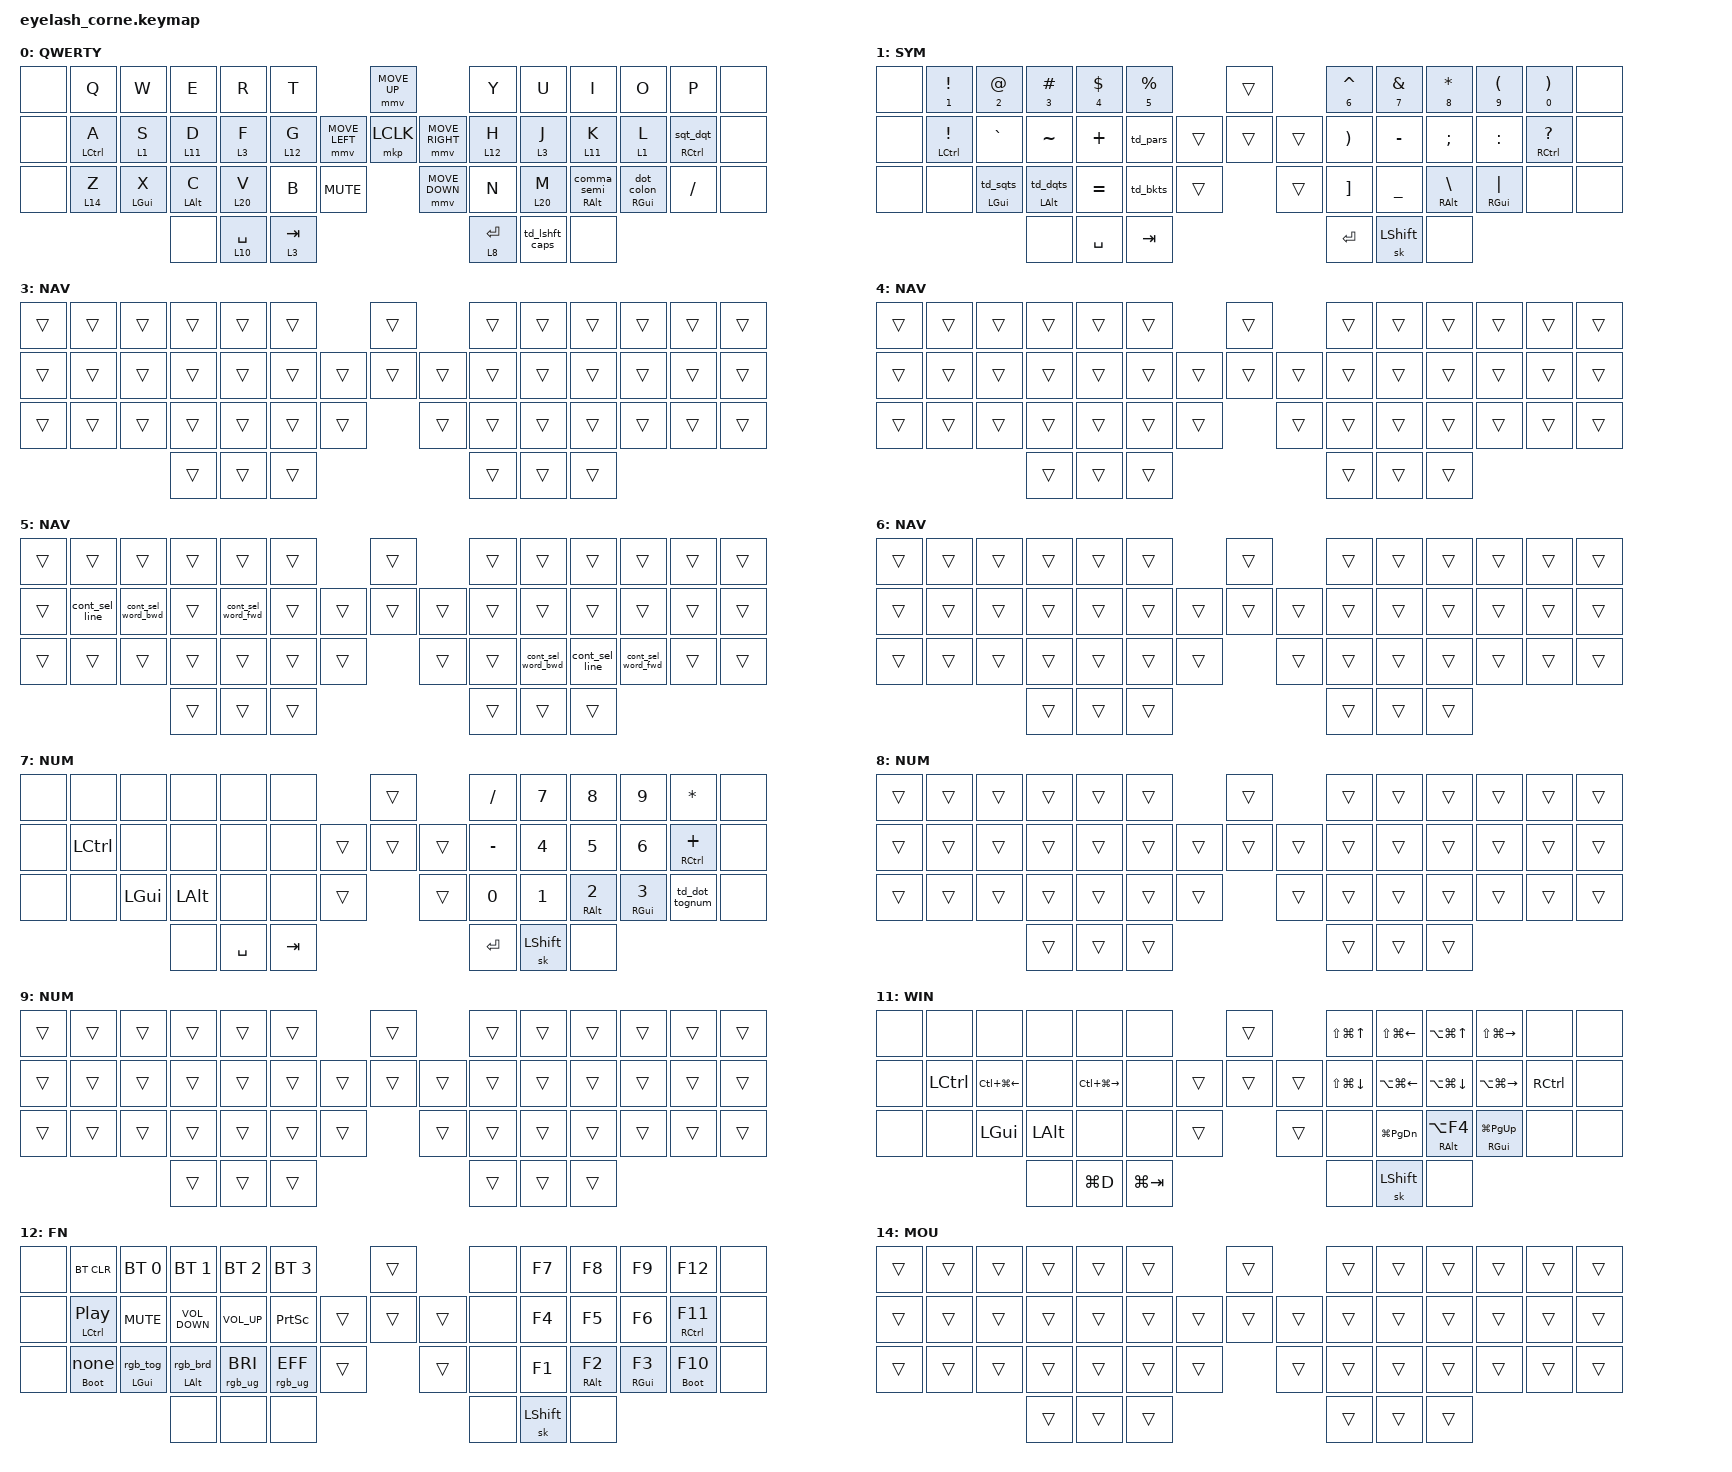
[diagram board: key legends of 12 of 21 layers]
#define ZMK_POINTING_DEFAULT_MOVE_VAL 400  // 600
#define ZMK_POINTING_DEFAULT_SCRL_VAL 100  // 10

#include <input/processors.dtsi>
#include <zephyr/dt-bindings/input/input-event-codes.h>
#include <behaviors.dtsi>
#include <dt-bindings/zmk/bt.h>
#include <dt-bindings/zmk/keys.h>
#include <dt-bindings/zmk/pointing.h>
#include <dt-bindings/zmk/rgb.h>

&mmv_input_listener { input-processors = <&zip_xy_scaler 2 1>; };

&msc_input_listener { input-processors = <&zip_scroll_scaler 2 1>; };

&msc {
    acceleration-exponent = <0>;      // 0
    time-to-max-speed-ms = <0>;       // 300
    delay-ms = <0>;                   // 0
};

&mmv {
    time-to-max-speed-ms = <200>;
    acceleration-exponent = <2>;
    trigger-period-ms = <16>;
};

&soft_off { hold-time-ms = <2000>; };

/ {
    behaviors {
        td_lshft_caps: td_lshft_caps {
            compatible = "zmk,behavior-tap-dance";
            display-name = "Shift/Caps Lock Tap Dance";
            #binding-cells = <0>;
            bindings = <&skq LEFT_SHIFT>, <&caps_word>, <&kp CAPS>;
        };

        td_bspc_bspcwd: td_bspc_bspcwd {
            compatible = "zmk,behavior-tap-dance";
            bindings = <&kp BSPC>, <&kp LC(BSPC)>;

            #binding-cells = <0>;
        };

        td_del_delwd: td_del_delwd {
            compatible = "zmk,behavior-tap-dance";
            bindings = <&kp DEL>, <&kp LC(DEL)>;

            #binding-cells = <0>;
        };

        td_pars: td_pars {
            compatible = "zmk,behavior-tap-dance";
            bindings = <&kp LPAR>, <&mc_pars>;

            #binding-cells = <0>;
        };

        td_abkts: td_abkts {
            compatible = "zmk,behavior-tap-dance";
            bindings = <&kp LESS_THAN>, <&mc_abkts>;

            #binding-cells = <0>;
        };

        td_bkts: td_bkts {
            compatible = "zmk,behavior-tap-dance";
            bindings = <&kp LBKT>, <&mc_bkts>;

            #binding-cells = <0>;
        };

        td_brcs: td_brcs {
            compatible = "zmk,behavior-tap-dance";
            bindings = <&kp LBRC>, <&mc_brcs>;

            #binding-cells = <0>;
        };

        td_sqts: td_sqts {
            compatible = "zmk,behavior-tap-dance";
            bindings = <&kp SQT>, <&mc_sqts>;

            #binding-cells = <0>;
        };

        td_dqts: td_dqts {
            compatible = "zmk,behavior-tap-dance";
            bindings = <&kp DQT>, <&mc_dqts>;

            #binding-cells = <0>;
        };

        td_tognav: td_tognav {
            compatible = "zmk,behavior-tap-dance";
            bindings = <&none>, <&tog 4>;

            #binding-cells = <0>;
        };

        td_dot_tognum: td_dot_tognum {
            compatible = "zmk,behavior-tap-dance";
            bindings = <&kp DOT>, <&tog 9>;

            #binding-cells = <0>;
        };

        td_togmou: td_togmou {
            compatible = "zmk,behavior-tap-dance";
            bindings = <&none>, <&tog 15>;

            #binding-cells = <0>;
        };

        mtq: mtq {
            compatible = "zmk,behavior-hold-tap";
            bindings = <&kp>, <&kp>;

            #binding-cells = <2>;
            tapping-term-ms = <200>;
            flavor = "balanced";
            quick-tap-ms = <175>;
        };

        mtq_mkp: mtq_mkp {
            compatible = "zmk,behavior-hold-tap";
            bindings = <&kp>, <&mkp>;

            #binding-cells = <2>;
            tapping-term-ms = <200>;
            flavor = "balanced";
            quick-tap-ms = <175>;
        };

        ltq: ltq {
            compatible = "zmk,behavior-hold-tap";
            bindings = <&mo>, <&kp>;

            #binding-cells = <2>;
            tapping-term-ms = <200>;
            flavor = "balanced";
            quick-tap-ms = <175>;
        };

        hml: hml {
            compatible = "zmk,behavior-hold-tap";
            bindings = <&kp>, <&kp>;

            #binding-cells = <2>;
            tapping-term-ms = <280>;
            require-prior-idle-ms = <150>;
            flavor = "balanced";
            quick-tap-ms = <175>;
            hold-trigger-on-release;
            hold-trigger-key-positions = <7 8 9 10 11 12 22 23 24 25 26 27 36 37 38 39 40 41 42 43 44 45 46 47>;
        };

        hmr: hmr {
            compatible = "zmk,behavior-hold-tap";
            bindings = <&kp>, <&kp>;

            #binding-cells = <2>;
            tapping-term-ms = <280>;
            require-prior-idle-ms = <150>;
            flavor = "balanced";
            quick-tap-ms = <175>;
            hold-trigger-on-release;
            hold-trigger-key-positions = <0 1 2 3 4 5 13 14 15 16 17 18 28 29 30 31 32 33 42 43 44 45 46 47 47>;
        };

        hml_sqt: hml_sqt {
            compatible = "zmk,behavior-hold-tap";
            bindings = <&kp>, <&td_sqts>;

            #binding-cells = <2>;
            tapping-term-ms = <280>;
            require-prior-idle-ms = <150>;
            flavor = "balanced";
            quick-tap-ms = <175>;
            hold-trigger-on-release;
            hold-trigger-key-positions = <7 8 9 10 11 12 22 23 24 25 26 27 36 37 38 39 40 41 42 43 44 45 46 47>;
        };

        hml_dqt: hml_dqt {
            compatible = "zmk,behavior-hold-tap";
            bindings = <&kp>, <&td_dqts>;

            #binding-cells = <2>;
            tapping-term-ms = <280>;
            require-prior-idle-ms = <150>;
            flavor = "balanced";
            quick-tap-ms = <175>;
            hold-trigger-on-release;
            hold-trigger-key-positions = <7 8 9 10 11 12 22 23 24 25 26 27 36 37 38 39 40 41 42 43 44 45 46 47>;
        };

        hml_sel_line: hml_sel_line {
            compatible = "zmk,behavior-hold-tap";
            bindings = <&kp>, <&sel_line>;

            #binding-cells = <2>;
            tapping-term-ms = <280>;
            require-prior-idle-ms = <150>;
            flavor = "balanced";
            quick-tap-ms = <175>;
            hold-trigger-on-release;
            hold-trigger-key-positions = <7 8 9 10 11 12 22 23 24 25 26 27 36 37 38 39 40 41 42 43 44 45 46 47>;
        };

        hml_rgb_tog: hml_rgb_tog {
            compatible = "zmk,behavior-hold-tap";
            bindings = <&kp>, <&rgb_tog>;

            #binding-cells = <2>;
            tapping-term-ms = <280>;
            require-prior-idle-ms = <150>;
            flavor = "balanced";
            quick-tap-ms = <175>;
            hold-trigger-on-release;
            hold-trigger-key-positions = <7 8 9 10 11 12 22 23 24 25 26 27 36 37 38 39 40 41 42 43 44 45 46 47>;
        };

        hml_rgb_brd: hml_rgb_brd {
            compatible = "zmk,behavior-hold-tap";
            bindings = <&kp>, <&rgb_brd>;

            #binding-cells = <2>;
            tapping-term-ms = <280>;
            require-prior-idle-ms = <150>;
            flavor = "balanced";
            quick-tap-ms = <175>;
            hold-trigger-on-release;
            hold-trigger-key-positions = <7 8 9 10 11 12 22 23 24 25 26 27 36 37 38 39 40 41 42 43 44 45 46 47>;
        };

        hmr_comma: hmr_comma {
            compatible = "zmk,behavior-hold-tap";
            bindings = <&kp>, <&comma_semi>;

            #binding-cells = <2>;
            tapping-term-ms = <280>;
            require-prior-idle-ms = <150>;
            flavor = "balanced";
            quick-tap-ms = <175>;
            hold-trigger-on-release;
            hold-trigger-key-positions = <0 1 2 3 4 5 13 14 15 16 17 18 28 29 30 31 32 33 42 43 44 45 46 47 47>;
        };

        hmr_dot: hmr_dot {
            compatible = "zmk,behavior-hold-tap";
            bindings = <&kp>, <&dot_colon>;

            #binding-cells = <2>;
            tapping-term-ms = <280>;
            require-prior-idle-ms = <150>;
            flavor = "balanced";
            quick-tap-ms = <175>;
            hold-trigger-on-release;
            hold-trigger-key-positions = <0 1 2 3 4 5 13 14 15 16 17 18 28 29 30 31 32 33 42 43 44 45 46 47 47>;
        };

        hmr_sqt: hmr_sqt {
            compatible = "zmk,behavior-hold-tap";
            bindings = <&kp>, <&sqt_dqt>;

            #binding-cells = <2>;
            tapping-term-ms = <280>;
            require-prior-idle-ms = <150>;
            flavor = "balanced";
            quick-tap-ms = <175>;
            hold-trigger-on-release;
            hold-trigger-key-positions = <0 1 2 3 4 5 13 14 15 16 17 18 28 29 30 31 32 33 42 43 44 45 46 47 47>;
        };

        hmr_sel_word_fwd: hmr_sel_word_fwd {
            compatible = "zmk,behavior-hold-tap";
            bindings = <&kp>, <&sel_word_fwd>;

            #binding-cells = <2>;
            tapping-term-ms = <280>;
            require-prior-idle-ms = <150>;
            flavor = "balanced";
            quick-tap-ms = <175>;
            hold-trigger-on-release;
            hold-trigger-key-positions = <0 1 2 3 4 5 13 14 15 16 17 18 28 29 30 31 32 33 42 43 44 45 46 47 47>;
        };

        hmr_sel_line: hmr_sel_line {
            compatible = "zmk,behavior-hold-tap";
            bindings = <&kp>, <&sel_line>;

            #binding-cells = <2>;
            tapping-term-ms = <280>;
            require-prior-idle-ms = <150>;
            flavor = "balanced";
            quick-tap-ms = <175>;
            hold-trigger-on-release;
            hold-trigger-key-positions = <0 1 2 3 4 5 13 14 15 16 17 18 28 29 30 31 32 33 42 43 44 45 46 47 47>;
        };

        hll: hll {
            compatible = "zmk,behavior-hold-tap";
            bindings = <&mo>, <&kp>;

            #binding-cells = <2>;
            tapping-term-ms = <280>;
            require-prior-idle-ms = <150>;
            flavor = "balanced";
            quick-tap-ms = <175>;
            hold-trigger-on-release;
            hold-trigger-key-positions = <7 8 9 10 11 12 22 23 24 25 26 27 36 37 38 39 40 41 42 43 44 45 46 47>;
        };

        hlr: hlr {
            compatible = "zmk,behavior-hold-tap";
            bindings = <&mo>, <&kp>;

            #binding-cells = <2>;
            tapping-term-ms = <280>;
            require-prior-idle-ms = <150>;
            flavor = "balanced";
            quick-tap-ms = <175>;
            hold-trigger-on-release;
            hold-trigger-key-positions = <0 1 2 3 4 5 13 14 15 16 17 18 28 29 30 31 32 33 42 43 44 45 46 47 47>;
        };

        as: as {
            compatible = "zmk,behavior-hold-tap";
            bindings = <&kp>, <&kp>;

            #binding-cells = <2>;
            tapping-term-ms = <135>;
            quick-tap-ms = <0>;
            flavor = "tap-preferred";
        };

        boot: boot {
            compatible = "zmk,behavior-hold-tap";
            bindings = <&bootloader>, <&none>;

            #binding-cells = <2>;
            tapping-term-ms = <2000>;
            flavor = "tap-preferred";
        };

        boot0: boot0 {
            compatible = "zmk,behavior-hold-tap";
            bindings = <&bootloader>, <&kp>;

            #binding-cells = <2>;
            tapping-term-ms = <2000>;
            flavor = "tap-preferred";
        };

        skq: skq {
            compatible = "zmk,behavior-sticky-key";
            bindings = <&kp>;
            #binding-cells = <1>;
            release-after-ms = <1000>;
            quick-release;
            ignore-modifiers;
        };

        sl_cont_sel: sl_cont_sel {
            compatible = "zmk,behavior-sticky-key";
            bindings = <&mo>;
            #binding-cells = <1>;
            release-after-ms = <5000>;
            quick-release;

            /delete-property/ ignore-modifiers;
        };

        lshft_caps: lshft_caps {
            compatible = "zmk,behavior-mod-morph";
            bindings = <&skq LEFT_SHIFT>, <&caps_word>;

            #binding-cells = <0>;
            mods = <(MOD_LSFT)>;
        };

        rshft_caps: rshft_caps {
            compatible = "zmk,behavior-mod-morph";
            bindings = <&skq RIGHT_SHIFT>, <&kp CAPS>;

            #binding-cells = <0>;
            mods = <(MOD_RSFT)>;
        };

        comma_semi: comma_semi {
            compatible = "zmk,behavior-mod-morph";
            bindings = <&kp COMMA>, <&kp SEMI>;

            #binding-cells = <0>;
            mods = <(MOD_LSFT|MOD_RSFT)>;
        };

        dot_colon: dot_colon {
            compatible = "zmk,behavior-mod-morph";
            bindings = <&kp DOT>, <&kp COLON>;

            #binding-cells = <0>;
            mods = <(MOD_LSFT|MOD_RSFT)>;
        };

        sqt_dqt: sqt_dqt {
            compatible = "zmk,behavior-mod-morph";
            bindings = <&td_sqts>, <&td_dqts>;

            #binding-cells = <0>;
            mods = <(MOD_LSFT|MOD_RSFT)>;
        };

        num_word: num_word {
            compatible = "zmk,behavior-auto-layer";
            #binding-cells = <1>;
            continue-list = <BSPC DEL DOT PLUS MINUS STAR FSLH>;
            ignore-numbers;
        };

        mou_word: mou_word {
            compatible = "zmk,behavior-auto-layer";
            #binding-cells = <1>;
            continue-list = <RET DOT COMMA FSLH SQT>;
            ignore-alphas;
            ignore-modifiers;
        };

        swapper: swapper {
            compatible = "zmk,behavior-tri-state";
            #binding-cells = <0>;
            bindings = <&kt LEFT_ALT>, <&kp TAB>, <&kt LEFT_ALT>;

            ignored-key-positions = <3>;
        };

        leader: leader {
            compatible = "zmk,behavior-leader-key";
            #binding-cells = <0>;
            ignore-keys = <LEFT_SHIFT RIGHT_SHIFT>;

            at {
                sequence = <A T>;
                bindings = <&kp AT>;
            };

            hash {
                sequence = <H A>;
                bindings = <&kp HASH>;
            };

            dllr {
                sequence = <D O>;
                bindings = <&kp DLLR>;
            };

            prcnt {
                sequence = <P C>;
                bindings = <&kp PRCNT>;
            };

            caret {
                sequence = <C T>;
                bindings = <&kp CARET>;
            };

            amps {
                sequence = <A M>;
                bindings = <&kp AMPS>;
            };
        };
    };

    rgb_encoder: rgb_encoder {
        compatible = "zmk,behavior-sensor-rotate";
        #sensor-binding-cells = <0>;
        bindings = <&rgb_ug RGB_BRI>, <&rgb_ug RGB_BRD>;
    };

    scroll_encoder: scroll_encoder {
        compatible = "zmk,behavior-sensor-rotate";
        #sensor-binding-cells = <0>;
        bindings = <&msc SCRL_DOWN>, <&msc SCRL_UP>;

        tap-ms = <100>;
    };

    combos {
        compatible = "zmk,combos";

        combo_softoff {
            bindings = <&soft_off>;
            key-positions = <1 15 29>;
            layers = <0>;
        };

        combo_esc {
            bindings = <&kp ESC>;
            key-positions = <15 16>;
            layers = <0 8 19>;
            timeout-ms = <30>;
            require-prior-idle-ms = <150>;
        };

        combo_esc0 {
            bindings = <&kp ESC>;
            key-positions = <36 37>;
            layers = <8>;
        };

        combo_esc1 {
            bindings = <&kp ESC>;
            key-positions = <22 23>;
            layers = <19>;
        };

        combo_tobse {
            bindings = <&to 0>;
            key-positions = <2 3>;
            layers = <15>;
        };

        combo_tobse0 {
            bindings = <&to 0>;
            key-positions = <15 16>;
            layers = <15>;
        };

        combo_leftshift {
            bindings = <&kp LEFT_SHIFT>;
            key-positions = <17 18>;
            timeout-ms = <50>;
            require-prior-idle-ms = <150>;
            layers = <0>;
        };

        combo_numword {
            bindings = <&num_word 8>;
            key-positions = <36 37>;
            timeout-ms = <50>;
            require-prior-idle-ms = <150>;
            layers = <0>;
        };

        combo_mouword {
            bindings = <&mou_macro>;
            key-positions = <22 23>;
            timeout-ms = <50>;
            require-prior-idle-ms = <150>;
            layers = <0>;
        };

        combo_leader {
            bindings = <&leader>;
            key-positions = <3 4>;
            timeout-ms = <20>;
            require-prior-idle-ms = <150>;
            layers = <0>;
        };

        combo_tomou {
            bindings = <&to 15>;
            key-positions = <2 3>;
            timeout-ms = <20>;
            require-prior-idle-ms = <150>;
            layers = <0>;
        };

        combo_tab {
            bindings = <&kp TAB>;
            key-positions = <16 17>;
            layers = <0 1 3 4 6 8 9>;
            timeout-ms = <50>;
            require-prior-idle-ms = <150>;
        };

        combo_ret {
            bindings = <&kp RET>;
            key-positions = <37 38>;
            timeout-ms = <50>;
            require-prior-idle-ms = <150>;
            layers = <0 1 3 4 6 8 9>;
        };

        combo_bspc {
            bindings = <&kp BSPC>;
            key-positions = <23 24>;
            layers = <0 1 3 4 6 8 9>;
            timeout-ms = <50>;
            require-prior-idle-ms = <150>;
        };

        combo_bspcwd {
            bindings = <&kp LC(BSPC)>;
            key-positions = <8 9>;
            timeout-ms = <30>;
            require-prior-idle-ms = <150>;
            layers = <0 1 3 4 6 8 9>;
        };

        combo_del {
            bindings = <&kp DEL>;
            key-positions = <24 25>;
            layers = <0 1 3 4 6 8 9>;
            timeout-ms = <30>;
            require-prior-idle-ms = <150>;
        };

        combo_delwd {
            bindings = <&kp LC(DEL)>;
            key-positions = <9 10>;
            timeout-ms = <20>;
            require-prior-idle-ms = <150>;
            layers = <0 1 3 4 6 8 9>;
        };

        combo_selall {
            bindings = <&kp LC(A)>;
            key-positions = <14 17>;
            timeout-ms = <30>;
            require-prior-idle-ms = <150>;
            layers = <0 1 3 4 6 8 9>;
        };

        combo_save {
            bindings = <&kp LC(S)>;
            key-positions = <15 17>;
            timeout-ms = <30>;
            require-prior-idle-ms = <150>;
            layers = <0 1 3 4 6 8 9>;
        };

        combo_undo {
            bindings = <&kp LC(Z)>;
            key-positions = <29 30>;
            timeout-ms = <50>;
            require-prior-idle-ms = <150>;
            layers = <0 1 3 4 6 8 9>;
        };

        combo_redo {
            bindings = <&kp LC(LS(Z))>;
            key-positions = <29 31>;
            timeout-ms = <50>;
            require-prior-idle-ms = <150>;
            layers = <0 1 3 4 6 8 9>;
        };

        combo_cut {
            bindings = <&kp LC(X)>;
            key-positions = <30 32>;
            timeout-ms = <50>;
            require-prior-idle-ms = <150>;
            layers = <0 1 3 4 6 8 9>;
        };

        combo_copy {
            bindings = <&kp LC(INS)>;
            key-positions = <30 31>;
            timeout-ms = <30>;
            require-prior-idle-ms = <150>;
            layers = <0 1 3 4 6 8 9>;
        };

        combo_paste {
            bindings = <&kp LS(INS)>;
            key-positions = <31 32>;
            timeout-ms = <50>;
            require-prior-idle-ms = <150>;
            layers = <0 1 3 4 6 8 9>;
        };

        combo_grave {
            bindings = <&kp GRAVE>;
            key-positions = <2 15>;
            timeout-ms = <50>;
            require-prior-idle-ms = <150>;
            layers = <0>;
        };

        combo_tilde {
            bindings = <&kp TILDE>;
            key-positions = <3 16>;
            timeout-ms = <50>;
            require-prior-idle-ms = <150>;
            layers = <0>;
        };

        combo_plus {
            bindings = <&kp PLUS>;
            key-positions = <4 17>;
            timeout-ms = <50>;
            require-prior-idle-ms = <150>;
            layers = <0>;
        };

        combo_lpar {
            bindings = <&td_pars>;
            key-positions = <5 18>;
            timeout-ms = <50>;
            require-prior-idle-ms = <150>;
            layers = <0>;
        };

        combo_rpar {
            bindings = <&kp RPAR>;
            key-positions = <7 22>;
            timeout-ms = <50>;
            require-prior-idle-ms = <150>;
            layers = <0>;
        };

        combo_minus {
            bindings = <&kp MINUS>;
            key-positions = <8 23>;
            timeout-ms = <50>;
            require-prior-idle-ms = <150>;
            layers = <0>;
        };

        combo_semi {
            bindings = <&kp SEMI>;
            key-positions = <9 24>;
            timeout-ms = <50>;
            require-prior-idle-ms = <150>;
            layers = <0>;
        };

        combo_colon {
            bindings = <&kp COLON>;
            key-positions = <10 25>;
            timeout-ms = <50>;
            require-prior-idle-ms = <150>;
            layers = <0>;
        };

        combo_excl {
            bindings = <&kp EXCL>;
            key-positions = <15 30>;
            timeout-ms = <50>;
            require-prior-idle-ms = <150>;
            layers = <0>;
        };

        combo_equal {
            bindings = <&kp EQUAL>;
            key-positions = <17 32>;
            timeout-ms = <50>;
            require-prior-idle-ms = <150>;
            layers = <0>;
        };

        combo_lbkt {
            bindings = <&td_bkts>;
            key-positions = <18 33>;
            timeout-ms = <50>;
            require-prior-idle-ms = <150>;
            layers = <0>;
        };

        combo_rbkt {
            bindings = <&kp RBKT>;
            key-positions = <22 36>;
            timeout-ms = <50>;
            require-prior-idle-ms = <150>;
            layers = <0>;
        };

        combo_under {
            bindings = <&kp UNDER>;
            key-positions = <23 37>;
            timeout-ms = <50>;
            require-prior-idle-ms = <150>;
            layers = <0>;
        };

        combo_question {
            bindings = <&kp QUESTION>;
            key-positions = <25 39>;
            timeout-ms = <50>;
            require-prior-idle-ms = <150>;
            layers = <0>;
        };

        combo_lbrc {
            bindings = <&td_brcs>;
            key-positions = <32 33>;
            layers = <1>;
        };

        combo_rbrc {
            bindings = <&kp RBRC>;
            key-positions = <36 37>;
            layers = <1>;
        };

        combo_lessthan {
            bindings = <&td_abkts>;
            key-positions = <17 18>;
            layers = <1>;
        };

        combo_greaterthan {
            bindings = <&kp GREATER_THAN>;
            key-positions = <22 23>;
            layers = <1>;
        };

        combo_mb4 {
            bindings = <&mkp MB4>;
            key-positions = <8 9>;
            layers = <14 15 16 17 18 19>;
        };

        combo_mb5 {
            bindings = <&mkp MB5>;
            key-positions = <9 10>;
            layers = <14 15 16 17 18 19>;
        };
    };

    macros {
        sel_word_fwd: sel_word_fwd {
            compatible = "zmk,behavior-macro";
            #binding-cells = <0>;
            bindings =
                <&macro_tap>,
                <&kp LC(RIGHT) &kp LC(LEFT)>,
                <&macro_press>,
                <&kp LC(LS(RIGHT))>,
                <&macro_pause_for_release>,
                <&macro_release>,
                <&kp LC(LS(RIGHT))>,
                <&macro_tap>,
                <&sl_cont_sel 6>;

            wait-ms = <0>;
            tap-ms = <0>;
        };

        sel_word_bwd: sel_word_bwd {
            compatible = "zmk,behavior-macro";
            #binding-cells = <0>;
            bindings =
                <&macro_tap>,
                <&kp LC(LEFT) &kp LC(RIGHT)>,
                <&macro_press>,
                <&kp LC(LS(LEFT))>,
                <&macro_pause_for_release>,
                <&macro_release>,
                <&kp LC(LS(LEFT))>,
                <&macro_tap>,
                <&sl_cont_sel 6>;

            wait-ms = <0>;
            tap-ms = <0>;
        };

        sel_line: sel_line {
            compatible = "zmk,behavior-macro";
            #binding-cells = <0>;
            bindings =
                <&macro_tap>,
                <&kp HOME &kp LS(END)>,
                <&macro_tap>,
                <&sl_cont_sel 6>;

            wait-ms = <0>;
            tap-ms = <0>;
        };

        cont_sel_word_fwd: cont_sel_word_fwd {
            compatible = "zmk,behavior-macro";
            #binding-cells = <0>;
            bindings =
                <&macro_press>,
                <&kp LC(LS(RIGHT))>,
                <&macro_pause_for_release>,
                <&macro_release>,
                <&kp LC(LS(RIGHT))>,
                <&macro_tap>,
                <&sl_cont_sel 6>;

            wait-ms = <0>;
            tap-ms = <0>;
        };

        cont_sel_word_bwd: cont_sel_word_bwd {
            compatible = "zmk,behavior-macro";
            #binding-cells = <0>;
            bindings =
                <&macro_press>,
                <&kp LC(LS(LEFT))>,
                <&macro_pause_for_release>,
                <&macro_release>,
                <&kp LC(LS(LEFT))>,
                <&macro_tap>,
                <&sl_cont_sel 6>;

            wait-ms = <0>;
            tap-ms = <0>;
        };

        cont_sel_line: cont_sel_line {
            compatible = "zmk,behavior-macro";
            #binding-cells = <0>;
            bindings =
                <&macro_press>,
                <&kp LS(DOWN)>,
                <&macro_pause_for_release>,
                <&macro_release>,
                <&kp LS(DOWN)>,
                <&macro_tap>,
                <&kp LS(END)>,
                <&macro_tap>,
                <&sl_cont_sel 6>;

            wait-ms = <0>;
            tap-ms = <0>;
        };

        mou_macro: mou_macro {
            compatible = "zmk,behavior-macro";
            #binding-cells = <0>;
            bindings = <&kp LEFT_CONTROL &mou_word 19>;
            wait-ms = <0>;
            tap-ms = <0>;
        };

        mc_pars: mc_pars {
            compatible = "zmk,behavior-macro";
            #binding-cells = <0>;
            bindings = <&kp LPAR &kp RPAR &kp LEFT>;
            wait-ms = <0>;
            tap-ms = <0>;
        };

        mc_abkts: mc_abkts {
            compatible = "zmk,behavior-macro";
            #binding-cells = <0>;
            bindings = <&kp LESS_THAN &kp GREATER_THAN &kp LEFT>;
            wait-ms = <0>;
            tap-ms = <0>;
        };

        mc_bkts: mc_bkts {
            compatible = "zmk,behavior-macro";
            #binding-cells = <0>;
            bindings = <&kp LBKT &kp RBKT &kp LEFT>;
            wait-ms = <0>;
            tap-ms = <0>;
        };

        mc_brcs: mc_brcs {
            compatible = "zmk,behavior-macro";
            #binding-cells = <0>;
            bindings = <&kp LBRC &kp RBRC &kp LEFT>;
            wait-ms = <0>;
            tap-ms = <0>;
        };

        mc_sqts: mc_sqts {
            compatible = "zmk,behavior-macro";
            #binding-cells = <0>;
            bindings = <&kp SQT &kp SQT &kp LEFT>;
            wait-ms = <0>;
            tap-ms = <0>;
        };

        mc_dqts: mc_dqts {
            compatible = "zmk,behavior-macro";
            #binding-cells = <0>;
            bindings = <&kp DQT &kp DQT &kp LEFT>;
            wait-ms = <0>;
            tap-ms = <0>;
        };

        rgb_tog: rgb_tog {
            compatible = "zmk,behavior-macro";
            #binding-cells = <0>;
            bindings = <&rgb_ug RGB_TOG>;
            wait-ms = <0>;
            tap-ms = <0>;
        };

        rgb_brd: rgb_brd {
            compatible = "zmk,behavior-macro";
            #binding-cells = <0>;
            bindings = <&rgb_ug RGB_BRD>;
            wait-ms = <0>;
            tap-ms = <0>;
        };
    };

    keymap {
        compatible = "zmk,keymap";

        base {
            display-name = "QWERTY";
            bindings = <
&none  &kp Q                &kp W        &kp E            &kp R          &kp T                                     &mmv MOVE_UP                     &kp Y       &kp U           &kp I                   &kp O            &kp P                     &none
&none  &hml LEFT_CONTROL A  &hll 1 S     &hll 11 D        &hll 3 F       &hll 12 G                 &mmv MOVE_LEFT  &mkp LCLK       &mmv MOVE_RIGHT  &hlr 12 H   &hlr 3 J        &hlr 11 K               &hlr 1 L         &hmr_sqt RIGHT_CONTROL 0  &none
&none  &hll 14 Z            &hml LGUI X  &hml LEFT_ALT C  &hll 20 V      &kp B       &kp C_MUTE                    &mmv MOVE_DOWN                   &kp N       &hlr 20 M       &hmr_comma RIGHT_ALT 0  &hmr_dot RGUI 0  &kp SLASH                 &none
                                         &none            &ltq 10 SPACE  &ltq 3 TAB                                                                 &ltq 8 RET  &td_lshft_caps  &none
            >;

            sensor-bindings = <&inc_dec_kp C_VOLUME_UP C_VOLUME_DOWN>;
        };

        symbol {
            display-name = "SYM";
            bindings = <
&none  &as N1 EXCL             &as N2 AT        &as N3 HASH          &as N4 DLLR  &as N5 PRCNT                    &trans          &as N6 CARET  &as N7 AMPS     &as N8 ASTRK         &as N9 LPAR     &as N0 RPAR                  &none
&none  &hml LEFT_CONTROL EXCL  &kp GRAVE        &kp TILDE            &kp PLUS     &td_pars                &trans  &trans  &trans  &kp RPAR      &kp MINUS       &kp SEMI             &kp COLON       &hmr RIGHT_CONTROL QUESTION  &none
&none  &none                   &hml_sqt LGUI 0  &hml_dqt LEFT_ALT 0  &kp EQUAL    &td_bkts      &trans            &trans          &kp RBKT      &kp UNDER       &hmr RIGHT_ALT BSLH  &hmr RGUI PIPE  &none                        &none
                                                &none                &kp SPACE    &kp TAB                                         &kp RET       &sk LEFT_SHIFT  &none
            >;

            sensor-bindings = <&scroll_encoder>;
        };

        navigation {
            display-name = "NAV";
            bindings = <
&none  &none                         &none            &none                  &none          &none                      &trans          &kp PG_UP  &as HOME LC(LEFT)  &kp UP                     &as END LC(RIGHT)         &kp LA(LC(LS(LG(P))))  &none
&none  &hml_sel_line LEFT_CONTROL 0  &sel_word_bwd    &none                  &sel_word_fwd  &none              &trans  &trans  &trans  &kp PG_DN  &kp LEFT           &kp DOWN                   &kp RIGHT                 &kp RIGHT_CONTROL      &none
&none  &kp LC(Z)                     &hml LGUI LC(X)  &hml LEFT_ALT LC(INS)  &kp LS(INS)    &none    &trans            &trans          &none      &sel_word_bwd      &hmr_sel_line RIGHT_ALT 0  &hmr_sel_word_fwd RGUI 0  &td_tognav             &none
                                                      &none                  &kp SPACE      &kp TAB                                    &kp RET    &sk LEFT_SHIFT     &none
            >;

            sensor-bindings = <&scroll_encoder>;
        };

        navigation_momentary {
            display-name = "NAV ";
            bindings = <
&trans  &trans  &trans  &trans  &trans  &trans                    &trans          &trans  &trans  &trans  &trans  &trans  &trans
&trans  &trans  &trans  &trans  &trans  &trans            &trans  &trans  &trans  &trans  &trans  &trans  &trans  &trans  &trans
&trans  &trans  &trans  &trans  &trans  &trans  &trans            &trans          &trans  &trans  &trans  &trans  &trans  &trans
                        &trans  &trans  &trans                                    &trans  &trans  &trans
            >;

            sensor-bindings = <&scroll_encoder>;
        };

        navigation_lock {
            display-name = "NAV ";
            bindings = <
&trans  &trans  &trans  &trans  &trans  &trans                    &trans          &trans  &trans  &trans  &trans  &trans  &trans
&trans  &trans  &trans  &trans  &trans  &trans            &trans  &trans  &trans  &trans  &trans  &trans  &trans  &trans  &trans
&trans  &trans  &trans  &trans  &trans  &trans  &trans            &trans          &trans  &trans  &trans  &trans  &trans  &trans
                        &trans  &trans  &trans                                    &trans  &trans  &trans
            >;

            sensor-bindings = <&scroll_encoder>;
        };

        navigation_cont_sel {
            display-name = "NAV ";
            bindings = <
&trans  &trans          &trans              &trans  &trans              &trans                    &trans          &trans  &trans              &trans          &trans              &trans  &trans
&trans  &cont_sel_line  &cont_sel_word_bwd  &trans  &cont_sel_word_fwd  &trans            &trans  &trans  &trans  &trans  &trans              &trans          &trans              &trans  &trans
&trans  &trans          &trans              &trans  &trans              &trans  &trans            &trans          &trans  &cont_sel_word_bwd  &cont_sel_line  &cont_sel_word_fwd  &trans  &trans
                                            &trans  &trans              &trans                                    &trans  &trans              &trans
            >;

            sensor-bindings = <&scroll_encoder>;
        };

        navigation_cont_sel_sl {
            display-name = "NAV ";
            bindings = <
&trans  &trans  &trans  &trans  &trans  &trans                    &trans          &trans  &trans  &trans  &trans  &trans  &trans
&trans  &trans  &trans  &trans  &trans  &trans            &trans  &trans  &trans  &trans  &trans  &trans  &trans  &trans  &trans
&trans  &trans  &trans  &trans  &trans  &trans  &trans            &trans          &trans  &trans  &trans  &trans  &trans  &trans
                        &trans  &trans  &trans                                    &trans  &trans  &trans
            >;

            sensor-bindings = <&scroll_encoder>;
        };

        numpad {
            display-name = "NUM";
            bindings = <
&none  &none             &none     &none         &none      &none                      &trans          &kp FSLH   &kp N7          &kp N8             &kp N9        &kp STAR                 &none
&none  &kp LEFT_CONTROL  &none     &none         &none      &none              &trans  &trans  &trans  &kp MINUS  &kp N4          &kp N5             &kp N6        &hmr RIGHT_CONTROL PLUS  &none
&none  &none             &kp LGUI  &kp LEFT_ALT  &none      &none    &trans            &trans          &kp N0     &kp NUMBER_1    &hmr RIGHT_ALT N2  &hmr RGUI N3  &td_dot_tognum           &none
                                   &none         &kp SPACE  &kp TAB                                    &kp RET    &sk LEFT_SHIFT  &none
            >;

            sensor-bindings = <&scroll_encoder>;
        };

        numpad_momentary {
            display-name = "NUM ";
            bindings = <
&trans  &trans  &trans  &trans  &trans  &trans                    &trans          &trans  &trans  &trans  &trans  &trans  &trans
&trans  &trans  &trans  &trans  &trans  &trans            &trans  &trans  &trans  &trans  &trans  &trans  &trans  &trans  &trans
&trans  &trans  &trans  &trans  &trans  &trans  &trans            &trans          &trans  &trans  &trans  &trans  &trans  &trans
                        &trans  &trans  &trans                                    &trans  &trans  &trans
            >;

            sensor-bindings = <&scroll_encoder>;
        };

        numpad_lock {
            display-name = "NUM ";
            bindings = <
&trans  &trans  &trans  &trans  &trans  &trans                    &trans          &trans  &trans  &trans  &trans  &trans  &trans
&trans  &trans  &trans  &trans  &trans  &trans            &trans  &trans  &trans  &trans  &trans  &trans  &trans  &trans  &trans
&trans  &trans  &trans  &trans  &trans  &trans  &trans            &trans          &trans  &trans  &trans  &trans  &trans  &trans
                        &trans  &trans  &trans                                    &trans  &trans  &trans
            >;

            sensor-bindings = <&scroll_encoder>;
        };

        application {
            display-name = "APP";
            bindings = <
&none  &none  &none              &kp LS(TAB)        &swapper           &kp LA(LC(LS(T)))                    &trans          &kp LA(LC(LS(Y)))  &none  &kp LA(LC(LS(I)))  &none  &none  &none
&none  &none  &kp LA(LC(LS(S)))  &none              &kp LA(LC(LS(F)))  &kp LA(LC(LS(G)))            &trans  &trans  &trans  &none              &none  &kp LA(LC(LS(K)))  &none  &none  &none
&none  &none  &none              &kp LA(LC(LS(C)))  &none              &none              &trans            &trans          &kp LA(LC(LS(N)))  &none  &none              &none  &none  &none
                                 &none              &none              &none                                                &none              &none  &none
            >;

            sensor-bindings = <&scroll_encoder>;
        };

        window {
            display-name = "WIN";
            bindings = <
&none  &none             &none                   &none         &none              &none                          &trans          &kp LS(LG(UP))    &kp LS(LG(LEFT))        &kp LA(LG(UP))          &kp LS(LG(RIGHT))    &none              &none
&none  &kp LEFT_CONTROL  &kp LC(LG(LEFT_ARROW))  &none         &kp LC(LG(RIGHT))  &none                  &trans  &trans  &trans  &kp LS(LG(DOWN))  &kp LA(LG(LEFT_ARROW))  &kp LA(LG(DOWN_ARROW))  &kp LA(LG(RIGHT))    &kp RIGHT_CONTROL  &none
&none  &none             &kp LGUI                &kp LEFT_ALT  &none              &none        &trans            &trans          &none             &kp LG(PG_DN)           &hmr RIGHT_ALT LA(F4)   &hmr RGUI LG(PG_UP)  &none              &none
                                                 &none         &kp LG(D)          &kp LG(TAB)                                    &none             &sk LEFT_SHIFT          &none
            >;

            sensor-bindings = <&scroll_encoder>;
        };

        function {
            display-name = "FN";
            bindings = <
&none  &bt BT_CLR                      &bt BT_SEL 0         &bt BT_SEL 1             &bt BT_SEL 2     &bt BT_SEL 3                       &trans          &none  &kp F7          &kp F8             &kp F9        &kp F12                 &none
&none  &hml LEFT_CONTROL C_PLAY_PAUSE  &kp C_MUTE           &kp C_VOLUME_DOWN        &kp C_VOLUME_UP  &kp PRINTSCREEN            &trans  &trans  &trans  &none  &kp F4          &kp F5             &kp F6        &hmr RIGHT_CONTROL F11  &none
&none  &boot 0 0                       &hml_rgb_tog LGUI 0  &hml_rgb_brd LEFT_ALT 0  &rgb_ug RGB_BRI  &rgb_ug RGB_EFF  &trans            &trans          &none  &kp F1          &hmr RIGHT_ALT F2  &hmr RGUI F3  &boot0 0 F10            &none
                                                            &none                    &none            &none                                              &none  &sk LEFT_SHIFT  &none
            >;

            sensor-bindings = <&scroll_encoder>;
        };

        mouse {
            display-name = "MOU";
            bindings = <
&none  &none             &none   &none   &none      &none                    &trans          &msc SCRL_UP    &mkp LCLK                 &mmv MOVE_UP    &mkp RCLK        &kp LA(LC(LS(LG(P))))  &none
&none  &kp LEFT_CONTROL  &mo 16  &mo 17  &mo 18     &none            &trans  &trans  &trans  &msc SCRL_DOWN  &mmv MOVE_LEFT            &mmv MOVE_DOWN  &mmv MOVE_RIGHT  &kp RIGHT_CONTROL      &none
&none  &none             &none   &none   &none      &none  &trans            &trans          &none           &msc SCRL_LEFT            &mkp MCLK       &msc SCRL_RIGHT  &td_togmou             &none
                                 &none   &mkp LCLK  &none                                    &none           &mtq_mkp LEFT_SHIFT LCLK  &none
            >;

            sensor-bindings = <&scroll_encoder>;
        };

        mouse_momentary {
            display-name = "MOU ";
            bindings = <
&trans  &trans  &trans  &trans  &trans  &trans                    &trans          &trans  &trans  &trans  &trans  &trans  &trans
&trans  &trans  &trans  &trans  &trans  &trans            &trans  &trans  &trans  &trans  &trans  &trans  &trans  &trans  &trans
&trans  &trans  &trans  &trans  &trans  &trans  &trans            &trans          &trans  &trans  &trans  &trans  &trans  &trans
                        &trans  &trans  &trans                                    &trans  &trans  &trans
            >;

            sensor-bindings = <&scroll_encoder>;
        };

        mouse_lock {
            display-name = "MOU ";
            bindings = <
&trans  &trans  &trans  &trans  &trans  &trans                    &trans          &trans  &trans  &trans  &trans  &trans  &trans
&trans  &trans  &trans  &trans  &trans  &trans            &trans  &trans  &trans  &trans  &trans  &trans  &trans  &trans  &trans
&trans  &trans  &trans  &trans  &trans  &trans  &trans            &trans          &trans  &trans  &trans  &trans  &trans  &trans
                        &trans  &trans  &trans                                    &trans  &trans  &trans
            >;

            sensor-bindings = <&scroll_encoder>;
        };

        mouse_xslow {
            display-name = "MOU ";
            bindings = <
&trans  &trans  &trans  &trans  &trans  &trans                    &trans          &msc MOVE_Y(10)   &trans            &mmv MOVE_Y(-40)  &trans           &trans  &trans
&trans  &trans  &trans  &trans  &trans  &trans            &trans  &trans  &trans  &msc MOVE_Y(-10)  &mmv MOVE_X(-40)  &mmv MOVE_Y(40)   &mmv MOVE_X(40)  &trans  &trans
&trans  &trans  &trans  &trans  &trans  &trans  &trans            &trans          &trans            &msc MOVE_X(-10)  &trans            &msc MOVE_X(10)  &trans  &trans
                        &trans  &trans  &trans                                    &trans            &trans            &trans
            >;

            sensor-bindings = <&scroll_encoder>;
        };

        mouse_slow {
            display-name = "MOU ";
            bindings = <
&trans  &trans  &trans  &trans  &trans  &trans                    &trans          &msc MOVE_Y(30)   &trans             &mmv MOVE_Y(-120)  &trans            &trans  &trans
&trans  &trans  &trans  &trans  &trans  &trans            &trans  &trans  &trans  &msc MOVE_Y(-30)  &mmv MOVE_X(-120)  &mmv MOVE_Y(120)   &mmv MOVE_X(120)  &trans  &trans
&trans  &trans  &trans  &trans  &trans  &trans  &trans            &trans          &trans            &msc MOVE_X(-30)   &trans             &msc MOVE_X(30)   &trans  &trans
                        &trans  &trans  &trans                                    &trans            &trans             &trans
            >;

            sensor-bindings = <&scroll_encoder>;
        };

        mouse_fast {
            display-name = "MOU ";
            bindings = <
&trans  &trans  &trans  &trans  &trans  &trans                    &trans          &msc MOVE_Y(400)   &trans              &mmv MOVE_Y(-1600)  &trans             &trans  &trans
&trans  &trans  &trans  &trans  &trans  &trans            &trans  &trans  &trans  &msc MOVE_Y(-400)  &mmv MOVE_X(-1600)  &mmv MOVE_Y(1600)   &mmv MOVE_X(1600)  &trans  &trans
&trans  &trans  &trans  &trans  &trans  &trans  &trans            &trans          &trans             &msc MOVE_X(-400)   &trans              &msc MOVE_X(400)   &trans  &trans
                        &trans  &trans  &trans                                    &trans             &trans              &trans
            >;

            sensor-bindings = <&scroll_encoder>;
        };

        mouse_free {
            display-name = "MOU ";
            bindings = <
&none  &kp Q                &kp W  &kp E  &kp R    &kp T                    &trans          &kp Y  &kp U                &kp I      &kp O    &kp LA(LC(LS(LG(P))))   &none
&none  &hml LEFT_CONTROL A  &kp S  &kp D  &kp F    &kp G            &trans  &trans  &trans  &kp H  &kp J                &kp K      &kp L    &hmr RIGHT_CONTROL SQT  &none
&none  &kp Z                &kp X  &kp C  &kp V    &kp B  &trans            &trans          &kp N  &kp M                &kp COMMA  &kp DOT  &kp FSLH                &none
                                   &none  &kp RET  &none                                    &none  &mtq LEFT_SHIFT RET  &none
            >;

            sensor-bindings = <&scroll_encoder>;
        };

        browser {
            display-name = "BRO";
            bindings = <
&none  &none          &kp LA(LC(LS(LG(W))))  &none          &kp LC(R)  &kp LC(T)                    &trans          &none         &kp LA(LEFT)   &none                &kp LA(RIGHT)  &none  &none
&none  &kp LC(LS(A))  &none                  &kp LC(LS(G))  &kp LC(G)  &none                &trans  &trans  &trans  &kp LA(HOME)  &kp LC(PG_UP)  &none                &kp LC(PG_DN)  &none  &none
&none  &none          &none                  &none          &none      &none      &trans            &trans          &kp LC(N)     &kp LA(F)      &as LC(LS(T)) LC(W)  &none          &none  &none
                                             &none          &kp SLASH  &kp LC(L)                                    &none         &none          &none
            >;

            sensor-bindings = <&scroll_encoder>;
        };
    };

    conditional_layers {
        compatible = "zmk,conditional-layers";

        continue_selection {
            if-layers = <2 6>;
            then-layer = <5>;
        };

        navigation_momentary {
            if-layers = <3>;
            then-layer = <2>;
        };

        navigation_lock {
            if-layers = <4>;
            then-layer = <2>;
        };

        numpad_momentary {
            if-layers = <8>;
            then-layer = <7>;
        };

        numpad_lock {
            if-layers = <9>;
            then-layer = <7>;
        };

        mouse_momentary {
            if-layers = <14>;
            then-layer = <13>;
        };

        mouse_lock {
            if-layers = <15>;
            then-layer = <13>;
        };
    };
};
